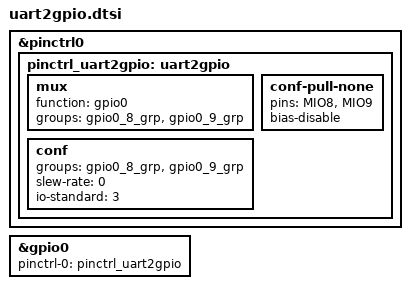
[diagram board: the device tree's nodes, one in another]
&pinctrl0 {
	pinctrl_uart2gpio: uart2gpio {
		mux {
			function = "gpio0";
			groups = "gpio0_8_grp", "gpio0_9_grp";
		};

		conf {
			groups = "gpio0_8_grp", "gpio0_9_grp";
			slew-rate = <0>;
			io-standard = <3>;  // LVCMOS33
		};

		conf-pull-none {
			pins = "MIO8", "MIO9";
			bias-disable;
		};
	};
};

&gpio0 {
	pinctrl-names = "default";
	pinctrl-0 = <&pinctrl_uart2gpio>;
};
